# MKL81Z7 register map
Vendor: Freescale Semiconductor, Inc.; Series: Kinetis_L; File version: 1.6
CPU: CM0PLUS r0p0, little endian, no MPU, no FPU, VTOR, 2 interrupt priority bits
Registers are 32-bit, read-write, reset 0x0 unless marked. A register's access mark holds for its fields unless they carry their own. Offsets are from the block's base; [hi:lo] are bit positions; {n}, {i} and the like mark numbered series; 'fields as' and 'values as' point back to an identical list.

## TRNG0
Base 0x40025000
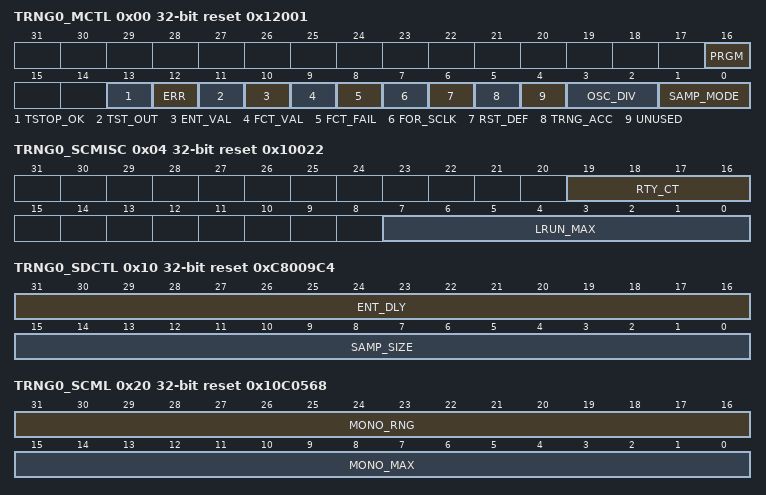
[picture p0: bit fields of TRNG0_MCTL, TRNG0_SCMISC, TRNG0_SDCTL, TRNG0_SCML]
0x00 TRNG0_MCTL reset 0x12001 — TRNG0 Miscellaneous Control Register
  [16] PRGM — Programming Mode Select
  [13] TSTOP_OK ro — TRNG_OK_TO_STOP
  [12] ERR — Read: Error status
  [11] TST_OUT ro — Read only: Test point inside ring oscillator.
  [10] ENT_VAL ro — Read only: Entropy Valid
  [9] FCT_VAL ro — Read only: Frequency Count Valid. Indicates that a valid frequency count may be read from FRQCNT.
  [8] FCT_FAIL ro — Read only: Frequency Count Fail
  [7] FOR_SCLK — Force System Clock
  [6] RST_DEF wo — Reset Defaults
  [5] TRNG_ACC — TRNG Access Mode
  [4] UNUSED — This bit is unused but write-able. Must be left as zero.
  [3:2] OSC_DIV — Oscillator Divide
    0=use ring oscillator with no divide; 1=use ring oscillator divided-by-2; 2=use ring oscillator divided-by-4; 3=use ring oscillator divided-by-8
  [1:0] SAMP_MODE — Sample Mode
    0=use Von Neumann data into both Entropy shifter and Statistical Checker; 1=use raw data into both Entropy shifter and Statistical Checker; 2=use Von Neumann data into Entropy shifter. Use raw data into Statistical Checker
0x04 TRNG0_SCMISC reset 0x10022 — TRNG0 Statistical Check Miscellaneous Register
  [19:16] RTY_CT — RETRY COUNT
  [7:0] LRUN_MAX — LONG RUN MAX LIMIT
0x08 TRNG0_PKRRNG reset 0x9A3 — TRNG0 Poker Range Register
  [15:0] PKR_RNG — Poker Range
0x0C TRNG0_PKRMAX reset 0x6920 (TRNG0 view) — TRNG0 Poker Maximum Limit Register
  [23:0] PKR_MAX — Poker Maximum Limit
0x0C TRNG0_PKRSQ ro (TRNG0 view) — TRNG0 Poker Square Calculation Result Register
  [23:0] PKR_SQ — Poker Square Calculation Result
0x10 TRNG0_SDCTL reset 0xC8009C4 — TRNG0 Seed Control Register
  [31:16] ENT_DLY — Entropy Delay
  [15:0] SAMP_SIZE — Sample Size
0x14 TRNG0_SBLIM reset 0x3F (TRNG0 view) — TRNG0 Sparse Bit Limit Register
  [9:0] SB_LIM — Sparse Bit Limit
0x14 TRNG0_TOTSAM ro (TRNG0 view) — TRNG0 Total Samples Register
  [19:0] TOT_SAM — Total Samples
0x18 TRNG0_FRQMIN reset 0x640 — TRNG0 Frequency Count Minimum Limit Register
  [21:0] FRQ_MIN — Frequency Count Minimum Limit
0x1C TRNG0_FRQCNT ro (TRNG0 view) — TRNG0 Frequency Count Register
  [21:0] FRQ_CT — Frequency Count
0x1C TRNG0_FRQMAX reset 0x6400 (TRNG0 view) — TRNG0 Frequency Count Maximum Limit Register
  [21:0] FRQ_MAX — Frequency Counter Maximum Limit
0x20 TRNG0_SCMC ro (TRNG0 view) — TRNG0 Statistical Check Monobit Count Register
  [15:0] MONO_CT — Monobit Count
0x20 TRNG0_SCML reset 0x10C0568 (TRNG0 view) — TRNG0 Statistical Check Monobit Limit Register
  [31:16] MONO_RNG — Monobit Range
  [15:0] MONO_MAX — Monobit Maximum Limit
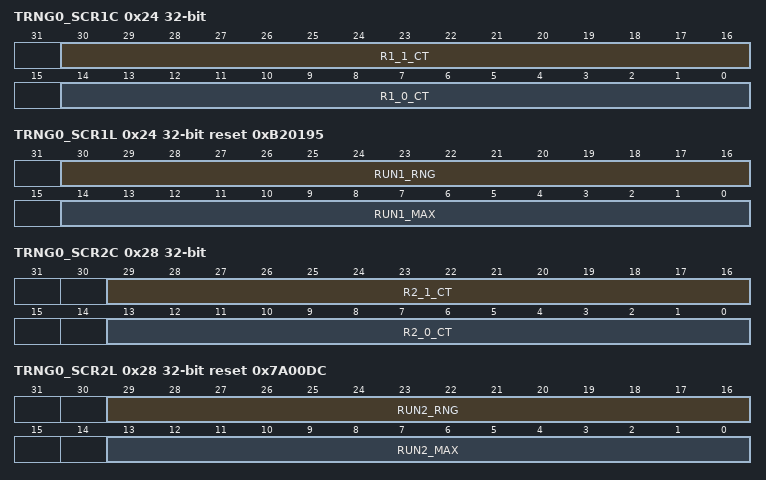
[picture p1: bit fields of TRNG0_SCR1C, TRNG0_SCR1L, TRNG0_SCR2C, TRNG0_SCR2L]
0x24 TRNG0_SCR1C ro (TRNG0 view) — TRNG0 Statistical Check Run Length 1 Count Register
  [30:16] R1_1_CT — Runs of One, Length 1 Count
  [14:0] R1_0_CT — Runs of Zero, Length 1 Count
0x24 TRNG0_SCR1L reset 0xB20195 (TRNG0 view) — TRNG0 Statistical Check Run Length 1 Limit Register
  [30:16] RUN1_RNG — Run Length 1 Range
  [14:0] RUN1_MAX — Run Length 1 Maximum Limit
0x28 TRNG0_SCR2C ro (TRNG0 view) — TRNG0 Statistical Check Run Length 2 Count Register
  [29:16] R2_1_CT — Runs of One, Length 2 Count
  [13:0] R2_0_CT — Runs of Zero, Length 2 Count
0x28 TRNG0_SCR2L reset 0x7A00DC (TRNG0 view) — TRNG0 Statistical Check Run Length 2 Limit Register
  [29:16] RUN2_RNG — Run Length 2 Range
  [13:0] RUN2_MAX — Run Length 2 Maximum Limit
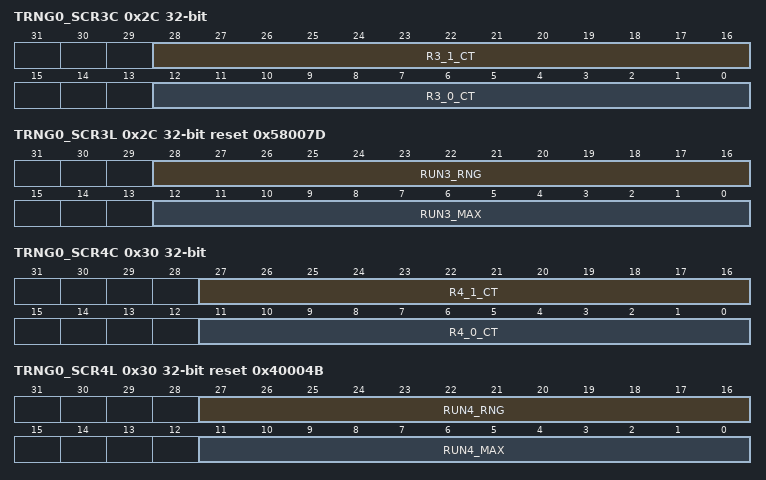
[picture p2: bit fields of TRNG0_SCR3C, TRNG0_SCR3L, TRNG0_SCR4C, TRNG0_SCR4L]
0x2C TRNG0_SCR3C ro (TRNG0 view) — TRNG0 Statistical Check Run Length 3 Count Register
  [28:16] R3_1_CT — Runs of Ones, Length 3 Count
  [12:0] R3_0_CT — Runs of Zeroes, Length 3 Count
0x2C TRNG0_SCR3L reset 0x58007D (TRNG0 view) — TRNG0 Statistical Check Run Length 3 Limit Register
  [28:16] RUN3_RNG — Run Length 3 Range
  [12:0] RUN3_MAX — Run Length 3 Maximum Limit
0x30 TRNG0_SCR4C ro (TRNG0 view) — TRNG0 Statistical Check Run Length 4 Count Register
  [27:16] R4_1_CT — Runs of One, Length 4 Count
  [11:0] R4_0_CT — Runs of Zero, Length 4 Count
0x30 TRNG0_SCR4L reset 0x40004B (TRNG0 view) — TRNG0 Statistical Check Run Length 4 Limit Register
  [27:16] RUN4_RNG — Run Length 4 Range
  [11:0] RUN4_MAX — Run Length 4 Maximum Limit
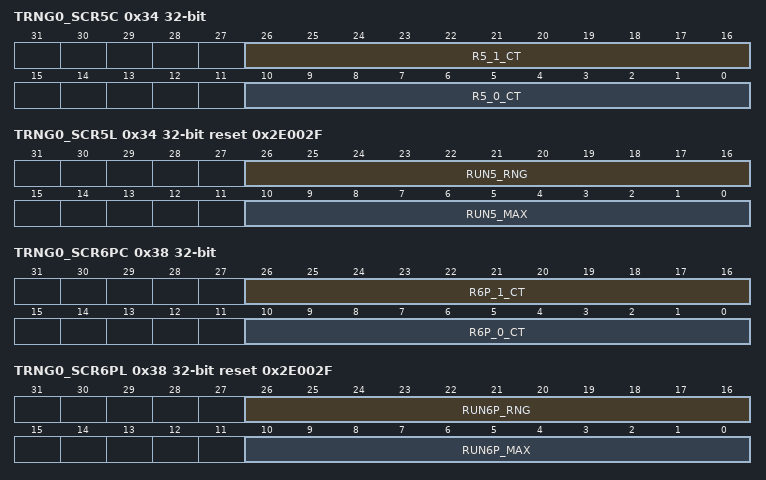
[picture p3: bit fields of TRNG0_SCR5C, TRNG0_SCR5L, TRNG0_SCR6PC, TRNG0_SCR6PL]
0x34 TRNG0_SCR5C ro (TRNG0 view) — TRNG0 Statistical Check Run Length 5 Count Register
  [26:16] R5_1_CT — Runs of One, Length 5 Count
  [10:0] R5_0_CT — Runs of Zero, Length 5 Count
0x34 TRNG0_SCR5L reset 0x2E002F (TRNG0 view) — TRNG0 Statistical Check Run Length 5 Limit Register
  [26:16] RUN5_RNG — Run Length 5 Range
  [10:0] RUN5_MAX — Run Length 5 Maximum Limit
0x38 TRNG0_SCR6PC ro (TRNG0 view) — TRNG0 Statistical Check Run Length 6+ Count Register
  [26:16] R6P_1_CT — Runs of One, Length 6+ Count
  [10:0] R6P_0_CT — Runs of Zero, Length 6+ Count
0x38 TRNG0_SCR6PL reset 0x2E002F (TRNG0 view) — TRNG0 Statistical Check Run Length 6+ Limit Register
  [26:16] RUN6P_RNG — Run Length 6+ Range
  [10:0] RUN6P_MAX — Run Length 6+ Maximum Limit
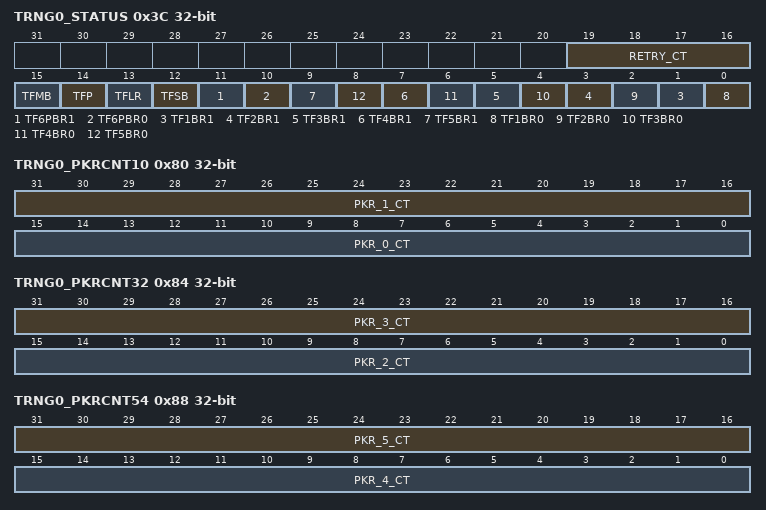
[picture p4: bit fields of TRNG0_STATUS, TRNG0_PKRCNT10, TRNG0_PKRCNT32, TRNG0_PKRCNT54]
0x3C TRNG0_STATUS ro
  [19:16] RETRY_CT — RETRY COUNT
  [15] TFMB — Test Fail, Mono Bit. If TFMB=1, the Mono Bit Test has failed.
  [14] TFP — Test Fail, Poker. If TFP=1, the Poker Test has failed.
  [13] TFLR — Test Fail, Long Run. If TFLR=1, the Long Run Test has failed.
  [12] TFSB — Test Fail, Sparse Bit. If TFSB=1, the Sparse Bit Test has failed.
  [11] TF6PBR1 — Test Fail, 6 Plus Bit Run, Sampling 1s
  [10] TF6PBR0 — Test Fail, 6 Plus Bit Run, Sampling 0s
  [2n-1] TF{n}BR1 (n=1..5) — Test Fail, {n}-Bit Run, Sampling 1s. If TF{n}BR1=1, the {n}-Bit Run, Sampling 1s Test has failed.
  [2n-2] TF{n}BR0 (n=1..5) — Test Fail, {n}-Bit Run, Sampling 0s. If TF{n}BR0=1, the {n}-Bit Run, Sampling 0s Test has failed.
{0x40+4i} TRNG0_ENT{i} ro (i=0..15) — RNG TRNG Entropy Read Register
  [31:0] ENT — Entropy Value
0x80 TRNG0_PKRCNT10 ro — TRNG0 Statistical Check Poker Count 1 and 0 Register
  [31:16] PKR_1_CT — Poker 1h Count
  [15:0] PKR_0_CT — Poker 0h Count
0x84 TRNG0_PKRCNT32 ro — TRNG0 Statistical Check Poker Count 3 and 2 Register
  [31:16] PKR_3_CT — Poker 3h Count
  [15:0] PKR_2_CT — Poker 2h Count
0x88 TRNG0_PKRCNT54 ro — TRNG0 Statistical Check Poker Count 5 and 4 Register
  [31:16] PKR_5_CT — Poker 5h Count
  [15:0] PKR_4_CT — Poker 4h Count
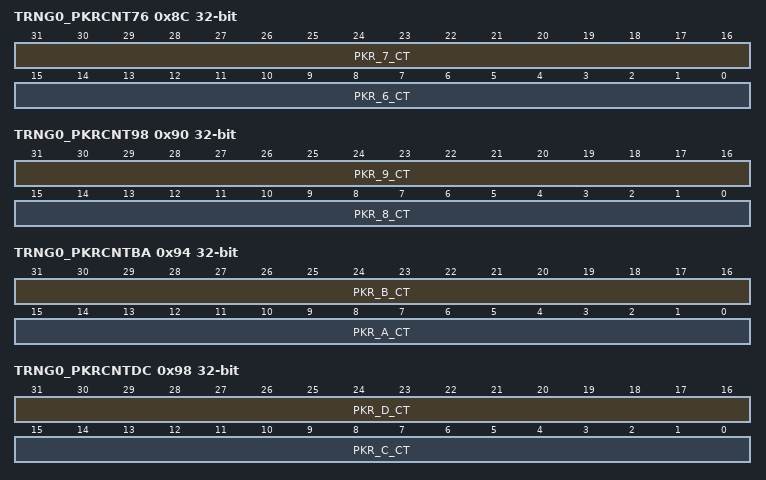
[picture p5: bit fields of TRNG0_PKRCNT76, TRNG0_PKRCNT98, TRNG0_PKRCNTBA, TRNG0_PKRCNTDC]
0x8C TRNG0_PKRCNT76 ro — TRNG0 Statistical Check Poker Count 7 and 6 Register
  [31:16] PKR_7_CT — Poker 7h Count
  [15:0] PKR_6_CT — Poker 6h Count
0x90 TRNG0_PKRCNT98 ro — TRNG0 Statistical Check Poker Count 9 and 8 Register
  [31:16] PKR_9_CT — Poker 9h Count
  [15:0] PKR_8_CT — Poker 8h Count
0x94 TRNG0_PKRCNTBA ro — TRNG0 Statistical Check Poker Count B and A Register
  [31:16] PKR_B_CT — Poker Bh Count
  [15:0] PKR_A_CT — Poker Ah Count
0x98 TRNG0_PKRCNTDC ro — TRNG0 Statistical Check Poker Count D and C Register
  [31:16] PKR_D_CT — Poker Dh Count
  [15:0] PKR_C_CT — Poker Ch Count
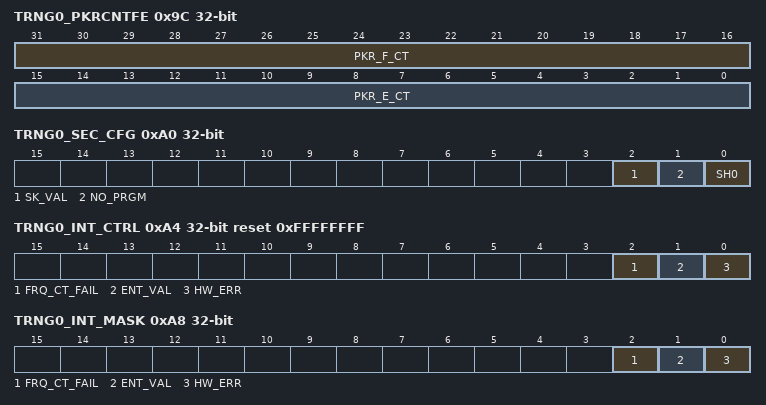
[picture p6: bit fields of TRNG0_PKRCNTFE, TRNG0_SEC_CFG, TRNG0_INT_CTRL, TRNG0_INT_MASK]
0x9C TRNG0_PKRCNTFE ro — TRNG0 Statistical Check Poker Count F and E Register
  [31:16] PKR_F_CT — Poker Fh Count
  [15:0] PKR_E_CT — Poker Eh Count
0xA0 TRNG0_SEC_CFG — TRNG0 Security Configuration Register
  [2] SK_VAL — Reserved. DRNG-specific, not applicable to this version.
    0=See DRNG version; 1=See DRNG version
  [1] NO_PRGM — If set the TRNG registers cannot be programmed
    0=Programability of registers controlled only by the TRNG0 Miscellaneous Control Register's access mode bit; 1=Overides TRNG0 Miscellaneous Control Register access mode and prevents TRNG register programming
  [0] SH0 — Reserved. DRNG specific, not applicable to this version.
    0=See DRNG version; 1=See DRNG version
0xA4 TRNG0_INT_CTRL reset 0xFFFFFFFF — TRNG0 Interrupt Control Register
  [2] FRQ_CT_FAIL — Same behavior as bit 0 above.
    0=Same behavior as bit 0 above; 1=Same behavior as bit 0 above
  [1] ENT_VAL — Same behavior as bit 0 above.
    values as FRQ_CT_FAIL
  [0] HW_ERR — Bit position that can be cleared if corresponding bit of INT_STATUS has been asserted.
    0=Corresponding bit of INT_STATUS cleared; 1=Corresponding bit of INT_STATUS active
0xA8 TRNG0_INT_MASK — TRNG0 Mask Register
  [2] FRQ_CT_FAIL — Same behavior as bit 0 above.
    values as TRNG0_INT_CTRL.FRQ_CT_FAIL
  [1] ENT_VAL — Same behavior as bit 0 above.
    values as TRNG0_INT_CTRL.FRQ_CT_FAIL
  [0] HW_ERR — Bit position that can be cleared if corresponding bit of INT_STATUS has been asserted.
    0=Corresponding interrupt of INT_STATUS is masked; 1=Corresponding bit of INT_STATUS is active
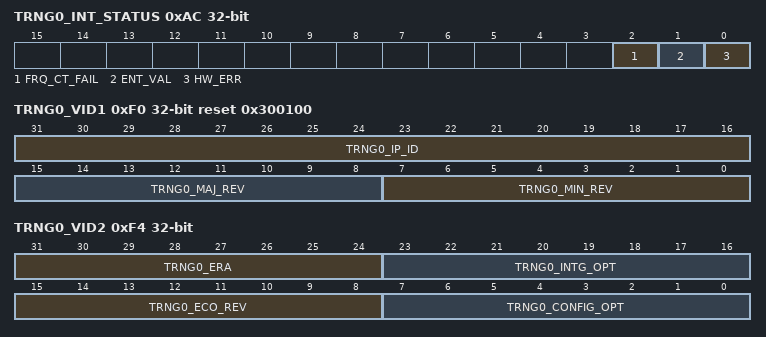
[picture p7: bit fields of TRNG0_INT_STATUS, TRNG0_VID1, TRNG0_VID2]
0xAC TRNG0_INT_STATUS — TRNG0 Interrupt Status Register
  [2] FRQ_CT_FAIL — Read only: Frequency Count Fail
    0=No hardware nor self test frequency errors; 1=The frequency counter has detected a failure
  [1] ENT_VAL ro — Read only: Entropy Valid
    0=Busy generation entropy. Any value read is invalid.; 1=TRNG can be stopped and entropy is valid if read
  [0] HW_ERR ro — Read: Error status
    0=no error; 1=error detected
0xF0 TRNG0_VID1 ro reset 0x300100 — TRNG0 Version ID Register (MS)
  [31:16] TRNG0_IP_ID — Shows the Freescale IP ID.
  [15:8] TRNG0_MAJ_REV — Shows the Freescale IP's Major revision of the TRNG.
    1=Major revision number for TRNG
  [7:0] TRNG0_MIN_REV — Shows the Freescale IP's Minor revision of the TRNG.
    0=Minor revision number for TRNG
0xF4 TRNG0_VID2 ro — TRNG0 Version ID Register (LS)
  [31:24] TRNG0_ERA — Shows the Freescale compile options for the TRNG.
    0=COMPILE_OPT for TRNG
  [23:16] TRNG0_INTG_OPT — Shows the Freescale integration options for the TRNG.
    0=INTG_OPT for TRNG
  [15:8] TRNG0_ECO_REV — Shows the Freescale IP's ECO revision of the TRNG.
    0=TRNG_ECO_REV for TRNG
  [7:0] TRNG0_CONFIG_OPT — Shows the Freescale IP's Configuaration options for the TRNG.
    0=TRNG_CONFIG_OPT for TRNG

## Notices in the file
Redistribution and use in source and binary forms, with or without modification,
are permitted provided that the following conditions are met:
o Redistributions of source code must retain the above copyright notice, this list
of conditions and the following disclaimer.
o Redistributions in binary form must reproduce the above copyright notice, this
list of conditions and the following disclaimer in the documentation and/or
other materials provided with the distribution.
o Neither the name of Freescale Semiconductor, Inc. nor the names of its
contributors may be used to endorse or promote products derived from this
software without specific prior written permission.
THIS SOFTWARE IS PROVIDED BY THE COPYRIGHT HOLDERS AND CONTRIBUTORS "AS IS" AND
ANY EXPRESS OR IMPLIED WARRANTIES, INCLUDING, BUT NOT LIMITED TO, THE IMPLIED
WARRANTIES OF MERCHANTABILITY AND FITNESS FOR A PARTICULAR PURPOSE ARE
DISCLAIMED. IN NO EVENT SHALL THE COPYRIGHT HOLDER OR CONTRIBUTORS BE LIABLE FOR
ANY DIRECT, INDIRECT, INCIDENTAL, SPECIAL, EXEMPLARY, OR CONSEQUENTIAL DAMAGES
(INCLUDING, BUT NOT LIMITED TO, PROCUREMENT OF SUBSTITUTE GOODS OR SERVICES;
LOSS OF USE, DATA, OR PROFITS; OR BUSINESS INTERRUPTION) HOWEVER CAUSED AND ON
ANY THEORY OF LIABILITY, WHETHER IN CONTRACT, STRICT LIABILITY, OR TORT
(INCLUDING NEGLIGENCE OR OTHERWISE) ARISING IN ANY WAY OUT OF THE USE OF THIS
SOFTWARE, EVEN IF ADVISED OF THE POSSIBILITY OF SUCH DAMAGE.
